# MCU_ADC0 register map
Vendor: Texas Instruments
Peripheral module from a debugger description file (folder J7VCL).
Registers are 32-bit, access per field, reset 0x0 unless marked. A register's access mark holds for its fields unless they carry their own. Offsets are as the file gives them; lines under a group give offsets from that group; [hi:lo] are bit positions; {n}, {i} and the like mark numbered series; 'fields as' and 'values as' point back to an identical list; <NAME> marks a mode.

## MCU_ADC0
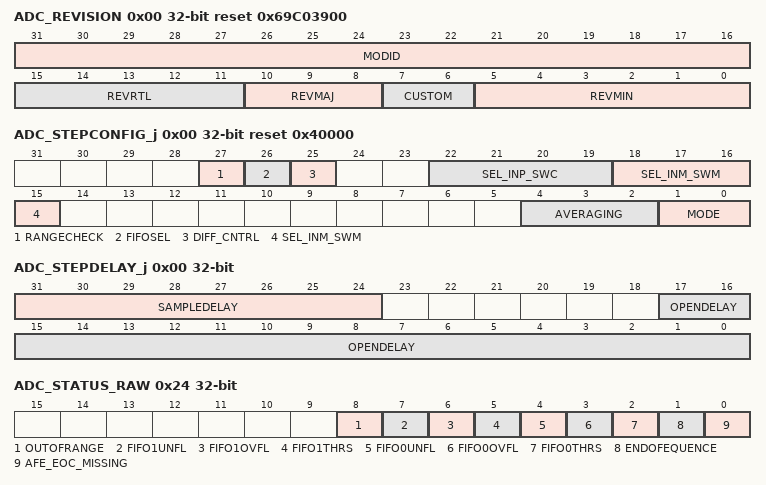
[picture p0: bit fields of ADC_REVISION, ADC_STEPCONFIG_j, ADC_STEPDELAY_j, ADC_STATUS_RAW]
0x00 ADC_REVISION ro reset 0x69C03900 — IP Revision Identifier (X.Y.R) Used by software to track features, bugs, and compatibility.
  [31:16] MODID — Module ID field
  [15:11] REVRTL — RTLADC_REVISION. Will vary depending on release.
  [10:8] REVMAJ — Major
  [7:6] CUSTOM
  [5:0] REVMIN — Minor
0x00 ADC_STEPCONFIG_j reset 0x40000 — The user should write the appropriate value to this register that is required to configure the various functions of each step. Offset = 64h + (j * 8h); where j = 0h to Fh
  [27] RANGECHECK rw — 0h = Disable ADC_RANGE check 1h = compare ADC data with ADC_RANGE
  [26] FIFOSEL rw — Sampled data will be stored in FIFO. 0h = FIFO0 1h = FIFO1
  [25] DIFF_CNTRL rw — DifferentialADC_CONTROL. 0h = Single ended input, SEL_INM_SWM must be 8h 1h = Differential input
  [22:19] SEL_INP_SWC rw — Select source for positive ADC input (INP). 0h = Input (channel) 0 1h = Input (channel) 1 2h = Input (channel) 2 3h = Input (channel) 3 4h = Input (channel) 4 5h = Input (channel) 5 6h = Input (channel) 6 7h = Input (channel) 7 8h = REFN
  [18:15] SEL_INM_SWM rw — Select source for negative ADC input (INM). 0h = Input (channel) 0 1h = Input (channel) 1 2h = Input (channel) 2 3h = Input (channel) 3 4h = Input (channel) 4 5h = Input (channel) 5 6h = Input (channel) 6 7h = Input (channel) 7 8h = REFN
  [4:2] AVERAGING rw — Number of samplings to average. 0h = no average 1h = 2 samples average 2h = 4 samples average 3h = 8 samples average 4h = 16 samples average
  [1:0] MODE rw — 0h = SW enabled, one-shot 1h = SW enabled, continuous 2h = HW synchronized, one-shot 3h = HW synchronized, continuous
0x00 ADC_STEPDELAY_j — Controls number of SMPL_CLK periods to sample and delay. Offset = 68h + (j × 8h); where j = 0h to Fh
  [31:24] SAMPLEDELAY rw — This register will control the number of SMPL_CLK cycles to sample the input signal (hold SOC high). Any value programmed here will be added to the minimum time of 2 SMPL_CLK cycles.
  [17:0] OPENDELAY rw — Program the number of SMPL_CLK cycles to wait after applying the step configuration registers and before sending the start of ADC conversion.
0x20 ADC_EOI — The End of Interrupt () Register allows the CPU to acknowledge completion of an interrupt by writing to the for interrupt sources. An eoi_write signal will be generated and another interrupt will be triggered if interrupt sources remain. This register will be reset one cycle after it has been written to. The EOI register is used to re-trigger the pulse interrupt signal to ensure that any nested interrupt events are serviced. The software interrupt handler must write to the EOI register at the end of the current interrupt processing routine, so that new events can re-trigger the pulse interrupt signal again. For level interrupt signals the EOI register is not functional and must not be used.
  [0] LINENUMEOI wo — Software End Of Interrupt (EOI) control.
0x24 ADC_STATUS_RAW access not given — The register allows the MCU_ADC0 interrupt sources to be manually set when writing a 1 to a specific bit. Write 0: No action Write 1: Set event Read 0: No event pending Read 1: Event pending
  [8] OUTOFRANGE — Status raw for out of range interrupt. (access RW1S)
  [7] FIFO1UNFL — Status raw for FIFO1 under-flow interrupt. (access RW1S)
  [6] FIFO1OVFL — Status raw for FIFO1 over-flow interrupt. (access RW1S)
  [5] FIFO1THRS — Status raw for FIFO1 threshold interrupt. (access RW1S)
  [4] FIFO0UNFL — Status raw for FIFO0 under-flow interrupt. (access RW1S)
  [3] FIFO0OVFL — Status raw for FIFO0 over-flow interrupt. (access RW1S)
  [2] FIFO0THRS — Status raw for FIFO0 threshold interrupt. (access RW1S)
  [1] ENDOFEQUENCE — Status raw for end of sequence interrupt. (access RW1S)
  [0] AFE_EOC_MISSING — Status raw for missing AFE EOC interrupt. (access RW1S)
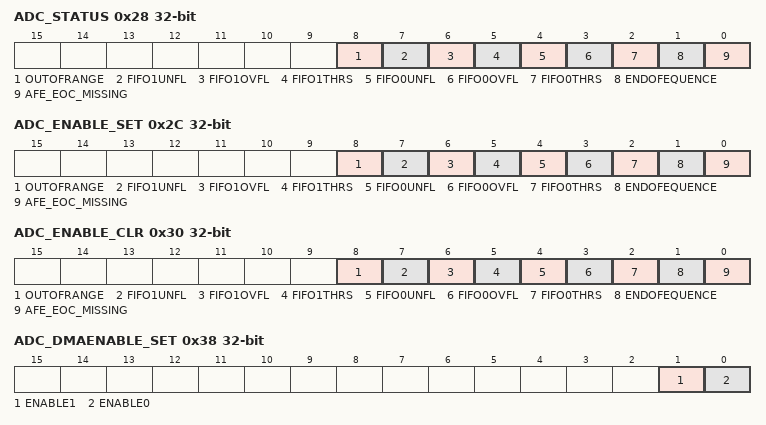
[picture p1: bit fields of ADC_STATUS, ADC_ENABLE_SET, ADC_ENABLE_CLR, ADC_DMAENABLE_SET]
0x28 ADC_STATUS access not given — The register allows the MCU_ADC0 interrupt sources to be manually cleared when writing a 1 to a specific bit. Write 0: No action Write 1: Clear event Read 0: No event pending Read 1: Event pending
  [8] OUTOFRANGE — Enabled status for out of range interrupt. (access RW1C)
  [7] FIFO1UNFL — Enabled status for FIFO1 under-flow interrupt. (access RW1C)
  [6] FIFO1OVFL — Enabled status for FIFO1 over-flow interrupt. (access RW1C)
  [5] FIFO1THRS — Enabled status for FIFO1 threshold interrupt. (access RW1C)
  [4] FIFO0UNFL — Enabled status for FIFO0 under-flow interrupt. (access RW1C)
  [3] FIFO0OVFL — Enabled status for FIFO0 over-flow interrupt. (access RW1C)
  [2] FIFO0THRS — Enabled status for FIFO0 threshold interrupt. (access RW1C)
  [1] ENDOFEQUENCE — Enabled status for end of sequence interrupt. (access RW1C)
  [0] AFE_EOC_MISSING — Enable status for missing AFE EOC interrupt. (access RW1C)
0x2C ADC_ENABLE_SET access not given — The register allows the MCU_ADC0 interrupt sources to be manually enabled when writing a 1 to a specific bit. Write 0: No action Write 1: Enable event Read 0: Event is disabled Read 1: Event is enabled
  [8] OUTOFRANGE — Out of range interrupt enable. (access RW1S)
  [7] FIFO1UNFL — FIFO1 under-flow interrupt enable. (access RW1S)
  [6] FIFO1OVFL — FIFO1 over-flow interrupt enable. (access RW1S)
  [5] FIFO1THRS — FIFO1 threshold interrupt enable. (access RW1S)
  [4] FIFO0UNFL — FIFO0 under-flow interrupt enable. (access RW1S)
  [3] FIFO0OVFL — FIFO0 over-flow interrupt enable. (access RW1S)
  [2] FIFO0THRS — FIFO0 threshold interrupt enable. (access RW1S)
  [1] ENDOFEQUENCE — End of sequence interrupt enable. (access RW1S)
  [0] AFE_EOC_MISSING — Missing AFE EOC interrupt enable. (access RW1S)
0x30 ADC_ENABLE_CLR access not given — The register allows the MCU_ADC0 interrupt sources to be manually disabled when writing a 1 to a specific bit. Write 0: No action Write 1: Disable event Read 0: Event is disabled Read 1: Event is enabled
  [8] OUTOFRANGE — Out of range interrupt disable. (access RW1C)
  [7] FIFO1UNFL — FIFO1 under-flow interrupt disable. (access RW1C)
  [6] FIFO1OVFL — FIFO1 over-flow interrupt disable. (access RW1C)
  [5] FIFO1THRS — FIFO1 threshold interrupt disable. (access RW1C)
  [4] FIFO0UNFL — FIFO0 under-flow interrupt disable. (access RW1C)
  [3] FIFO0OVFL — FIFO0 over-flow interrupt disable. (access RW1C)
  [2] FIFO0THRS — FIFO0 threshold interrupt disable. (access RW1C)
  [1] ENDOFEQUENCE — End of sequence interrupt disable. (access RW1C)
  [0] AFE_EOC_MISSING — Missing AFE EOC interrupt disable. (access RW1C)
0x38 ADC_DMAENABLE_SET access not given — The register allows the enabling of DMA requests.
  [1] ENABLE1 — Enable DMA event to FIFO1 (access RW1S)
  [0] ENABLE0 — Enable DMA event to FIFO0 (access RW1S)
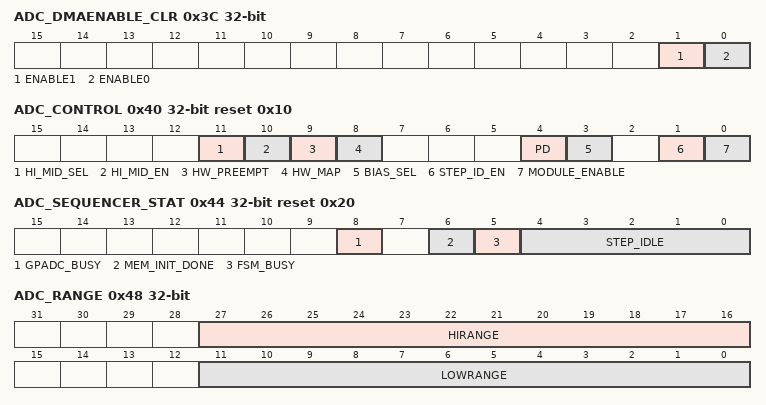
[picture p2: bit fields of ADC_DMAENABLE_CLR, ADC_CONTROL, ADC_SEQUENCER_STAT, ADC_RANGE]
0x3C ADC_DMAENABLE_CLR access not given — The register allows the disabling of DMA requests.
  [1] ENABLE1 — Clears the enable of the DMA event to FIFO1. Disable DMA event to FIFO1 Write 0h = No action Write 1h = Disable DMA event Read 0h = DMA event disabled Read 1h = DMA event enabled (access RW1C)
  [0] ENABLE0 — Clears the enable of the DMA event to FIFO0. Disable DMA event to FIFO0 Write 0h = No action Write 1h = Disable DMA event Read 0h = DMA event disabled Read 1h = DMA event enabled (access RW1C)
0x40 ADC_CONTROL reset 0x10 — Controls various parameters of the cotroller state.
  [11] HI_MID_SEL rw — Reference select for functional internal diagnostic debug mode. 0h = VMID 1h = REFP
  [10] HI_MID_EN rw — Functional internal diagnostic debug mode. 0h = disabled 1h = enabled
  [9] HW_PREEMPT rw — 0h = SW steps are not preempted by HW events 1h = SW steps are preempted by HW events
  [8] HW_MAP rw — 0h = HW events are disabled 1h = HW events are enabled
  [4] PD rw — ADC Power Down control. 0h = AFE is powered up 1h = AFE is powered down (default) At default, AFE is powered down; Software must write 0 to turn on the power and wait 4 us before starting a conversion
  [3] BIAS_SEL rw — AFE select bias ADC control register
  [1] STEP_ID_EN rw — Writing 1 to this bit will store the Step ID number with the captured ADC data in the FIFO. 0h = Write zeros 1h = Store the input (channel) ID tag
  [0] MODULE_ENABLE rw — ADC module enable bit. After programming all the configuration and step enable registers, write a 1 to this bit to start conversion. Writing a 0 will disable the module after the current conversion. Before turning on again, the ADC_SEQUENCER_STAT register show read back STEP_IDLE = 10h and FSM_BUSY = 0h. Enabling the controller will be held off until MEM_INIT_DONE = 1h.
0x44 ADC_SEQUENCER_STAT ro reset 0x20 — SW can read this register to find out the currently scheduled step id being converted on the ADC port. If you want to turn the controller off and then back on, the step_id bit should be checked and compared to IDLE before enabling the ADC module again. Also, before enabling the controller again, the user should wait for the FSM bit 5 to read idl.
  [8] GPADC_BUSY — Monitor the AFE internal calibration (busy bit)
  [6] MEM_INIT_DONE — ADC_STATUS of RAM initialization for ECC. 1h = RAM initialization to 0 after reset is done.
  [5] FSM_BUSY — ADC_STATUS of FSM. 0h = Idle 1h = Conversion in progress
  [4:0] STEP_IDLE — 10h = Idle 0h - Fh = Corresponds to Step 1 - Step 16
0x48 ADC_RANGE — This feature requires the check interrupt bit to be enabled first. The user can decide which input (channel) is compared by programming the RangeCheck bit of the Registers. It is up to software to sort through FIFO data to determine which input (channel) data was out of .
  [27:16] HIRANGE rw — Sampled ADC data is compared to this value. If the sampled data is &gt; HIRANGE, then interrupt is generated.
  [11:0] LOWRANGE rw — Sampled ADC data is compared to this value. If the sampled data is &lt; LOWRANGE, then interrupt is generated.
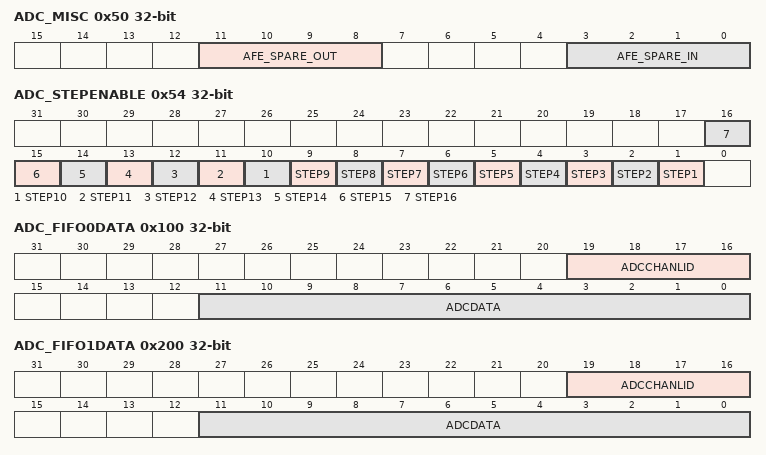
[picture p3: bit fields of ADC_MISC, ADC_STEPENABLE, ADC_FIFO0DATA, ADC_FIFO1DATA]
0x50 ADC_MISC — Spare inputs of the AFE are driven by this register, spare outputs from the AFE are read.
  [11:8] AFE_SPARE_OUT ro — Connected to AFE Spare Output pins, reserved in normal operation.
  [3:0] AFE_SPARE_IN rw — Connected to AFE Spare Input pins, reserved in normal operation.
0x54 ADC_STEPENABLE — Contains the enable bit for each step in the sequencer. When all steps are disabled, the FSM will stay in IDLE state.
  [n] STEP{n} rw (n=1..16) — Enable step {n}
0xE4 ADC_FIFO0WC ro — FIFO word count
  [8:0] NUMWDS — Number of words currently in the FIFO0.
0xE8 ADC_FIFO0THRESHOLD — FIFO threshold
  [7:0] THRESHOLD rw — Program the desired FIFO0 data sample level minus 1 to reach before generating interrupt to CPU.
0xEC ADC_FIFO0DMAREQ — DMA request.
  [7:0] DMAREQLEVEL rw — Number of words in FIFO0 before generating a DMA request.
0xF0 ADC_FIFO1WC ro — FIFO word count
  [8:0] NUMWDS — Number of words currently in the FIFO1.
0xF4 ADC_FIFO1THRESHOLD — FIFO threshold
  [7:0] THRESHOLD rw — Program the desired FIFO1 data sample level minus 1 to reach before generating interrupt to CPU.
0xF8 ADC_FIFO1DMAREQ — DMA request.
  [7:0] DMAREQLEVEL rw — Number of words in FIFO1 before generating a DMA request.
0x100 ADC_FIFO0DATA ro — A read from this register will auto increment the FIFO read pointer. If you read when FIFO is empty, it will trigger an underflow interrupt.
  [19:16] ADCCHANLID — Optional ID tag of input (channel) that captured the data. If tag option is disabled, these bits will be 0.
  [11:0] ADCDATA — Sampled ADC converted data value stored in FIFO0.
0x200 ADC_FIFO1DATA ro — A read from this register will auto increment the FIFO read pointer. If you read when FIFO is empty, it will trigger an underflow interrupt.
  [19:16] ADCCHANLID — Optional ID tag of input (channel) that captured the data. If tag option is disabled, these bits will be 0.
  [11:0] ADCDATA — Sampled ADC converted data value stored in FIFO1.
